# DPHY_RX1_VBUS2APB_WRAP_VBUSP_K3_DPHY_RX register map
Vendor: Texas Instruments
Peripheral module from a debugger description file (folder J721S2).
Registers are 32-bit, read-write, reset values left out (the file's numbers can be read two ways) unless marked. A register's access mark holds for its fields unless they carry their own. Offsets are as the file gives them; lines under a group give offsets from that group; [hi:lo] are bit positions; {n}, {i} and the like mark numbered series; 'fields as' and 'values as' point back to an identical list; <NAME> marks a mode.

## DPHY_RX1_VBUS2APB_WRAP_VBUSP_K3_DPHY_RX
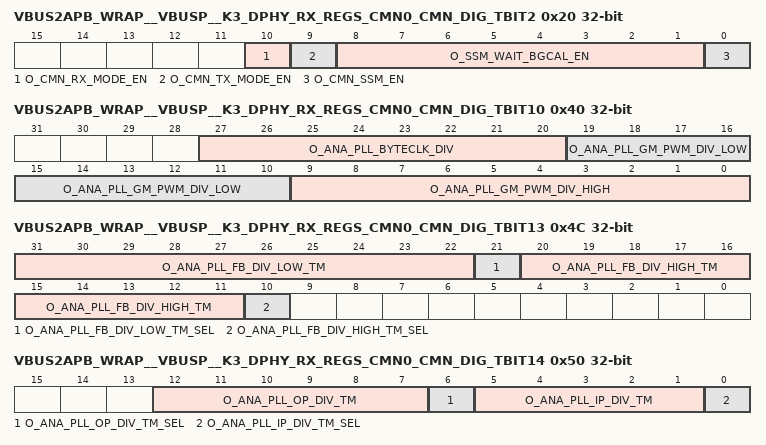
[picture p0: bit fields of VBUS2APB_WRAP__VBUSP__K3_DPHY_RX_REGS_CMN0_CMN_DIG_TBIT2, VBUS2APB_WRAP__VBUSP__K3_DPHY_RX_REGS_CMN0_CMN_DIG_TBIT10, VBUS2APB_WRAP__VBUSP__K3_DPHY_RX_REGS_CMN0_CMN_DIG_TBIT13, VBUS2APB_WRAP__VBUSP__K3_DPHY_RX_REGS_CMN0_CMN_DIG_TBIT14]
0x20 VBUS2APB_WRAP__VBUSP__K3_DPHY_RX_REGS_CMN0_CMN_DIG_TBIT2 — CMN_DIG_TBIT2
  [10] O_CMN_RX_MODE_EN — Enable CMN RX related StateMachines
  [9] O_CMN_TX_MODE_EN — Enable CMN TX related StateMachines
  [8:1] O_SSM_WAIT_BGCAL_EN — Wait time for Calibrations enable after bandgap is enabled [in us]
  [0] O_CMN_SSM_EN — Enable CMN startup state machine
0x40 VBUS2APB_WRAP__VBUSP__K3_DPHY_RX_REGS_CMN0_CMN_DIG_TBIT10 — CMN_DIG_TBIT10
  [27:20] O_ANA_PLL_BYTECLK_DIV — Byteclk divider value
  [19:10] O_ANA_PLL_GM_PWM_DIV_LOW — Low division value setting for the gm PWM control divider
  [9:0] O_ANA_PLL_GM_PWM_DIV_HIGH — High division value setting for the gm PWM control divider
0x4C VBUS2APB_WRAP__VBUSP__K3_DPHY_RX_REGS_CMN0_CMN_DIG_TBIT13 — CMN_DIG_TBIT13
  [31:22] O_ANA_PLL_FB_DIV_LOW_TM — forced value for pll_fb_div_clk_low
  [21] O_ANA_PLL_FB_DIV_LOW_TM_SEL — pll_fb_div_clk_low forced from test registers
  [20:11] O_ANA_PLL_FB_DIV_HIGH_TM — forced value for pll_fb_div_clk_high
  [10] O_ANA_PLL_FB_DIV_HIGH_TM_SEL — pll_fb_div_clk_high forced from test registers
0x50 VBUS2APB_WRAP__VBUSP__K3_DPHY_RX_REGS_CMN0_CMN_DIG_TBIT14 — CMN_DIG_TBIT14
  [12:7] O_ANA_PLL_OP_DIV_TM — forced value for op_div
  [6] O_ANA_PLL_OP_DIV_TM_SEL — op_div forced from test registers
  [5:1] O_ANA_PLL_IP_DIV_TM — forced value for ip_div
  [0] O_ANA_PLL_IP_DIV_TM_SEL — ip_div forced from test registers
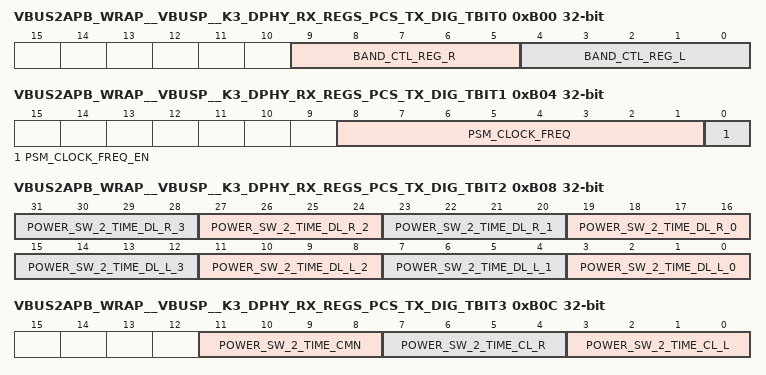
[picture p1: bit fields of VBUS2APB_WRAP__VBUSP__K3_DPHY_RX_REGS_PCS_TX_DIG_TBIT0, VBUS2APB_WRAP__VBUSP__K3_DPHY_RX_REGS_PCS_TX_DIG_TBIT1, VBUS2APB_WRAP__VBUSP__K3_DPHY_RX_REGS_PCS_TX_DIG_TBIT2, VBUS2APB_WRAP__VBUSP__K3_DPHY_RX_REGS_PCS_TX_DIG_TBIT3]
0xB00 VBUS2APB_WRAP__VBUSP__K3_DPHY_RX_REGS_PCS_TX_DIG_TBIT0 — PHY_BAND_CONTROL
  [9:5] BAND_CTL_REG_R — Data Rate [80_100] MHz
  [4:0] BAND_CTL_REG_L — Data Rate [80_100] MHz
0xB04 VBUS2APB_WRAP__VBUSP__K3_DPHY_RX_REGS_PCS_TX_DIG_TBIT1 — PHY_PSM_CONFIG
  [8:1] PSM_CLOCK_FREQ — psm_clock freq value
  [0] PSM_CLOCK_FREQ_EN — take psm_clock_freq from tbit
0xB08 VBUS2APB_WRAP__VBUSP__K3_DPHY_RX_REGS_PCS_TX_DIG_TBIT2 — PHY_PI_PH2_DL_CONFIG
  [4n+19:4n+16] POWER_SW_2_TIME_DL_R_{n} (n=0..3), [4n+3:4n] POWER_SW_2_TIME_DL_L_{n} (n=0..3)
0xB0C VBUS2APB_WRAP__VBUSP__K3_DPHY_RX_REGS_PCS_TX_DIG_TBIT3 — PHY_PI_PH2_CL_CMN_CONFIG
  [11:8] POWER_SW_2_TIME_CMN, [7:4] POWER_SW_2_TIME_CL_R, [3:0] POWER_SW_2_TIME_CL_L
